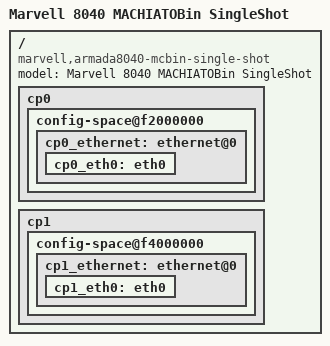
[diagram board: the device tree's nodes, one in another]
// SPDX-License-Identifier: (GPL-2.0+ OR MIT)
/*
 * Copyright (C) 2016 Marvell Technology Group Ltd.
 *
 * Device Tree for MACCHIATOBin SingleShot Armada 8040 community board platform
 * Difference from MACCHIATOBin DoubleShot:
 *   doesn't have two Copper 3310 PHYs connected to port 0 on each CP110
 */

#include "armada-8040-mcbin.dts"

/ {
	model = "Marvell 8040 MACHIATOBin SingleShot";
	compatible = "marvell,armada8040-mcbin-single-shot",
			"marvell,armada8040-mcbin",
			"marvell,armada8040", "marvell,armada-ap806-quad",
			"marvell,armada-ap806";

	cp0 {
		config-space@f2000000 {
			cp0_ethernet: ethernet@0 {
				cp0_eth0: eth0 {
					/delete-property/phy;
				};
			};
			/delete-node/cp0_xmdio;
		};
	};

	cp1 {
		config-space@f4000000 {
			cp1_ethernet: ethernet@0 {
				cp1_eth0: eth0 {
					/delete-property/phy;
				};
			};
			/delete-node/cp1_xmdio;
		};
	};
};

